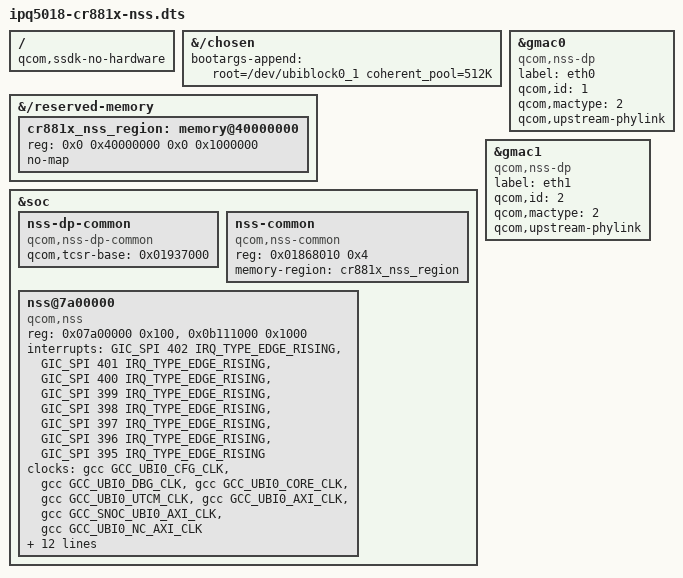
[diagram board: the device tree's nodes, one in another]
// SPDX-License-Identifier: (GPL-2.0+)
/* Native qosmio NSS variant. The ordinary CR881x DTS stays on stmmac. */
#include "ipq5018-cr881x.dts"

&{/chosen} {
	/* MPD temporary buffers use sleepable DMA allocations (patch 0828). */
	bootargs-append = " root=/dev/ubiblock0_1 coherent_pool=512K";
};

/ {
	/* SSDK provides link symbols only; YT921x and UNIPHY own the hardware. */
	qcom,ssdk-no-hardware;
};

&{/reserved-memory} {
	/* IPQ5018 MP firmware load region; opt-in for this 256 MiB profile. */
	cr881x_nss_region: memory@40000000 {
		reg = <0x0 0x40000000 0x0 0x1000000>;
		no-map;
	};
};

&soc {
	nss-dp-common {
		compatible = "qcom,nss-dp-common";
		qcom,tcsr-base = <0x01937000>;
	};

	nss-common {
		compatible = "qcom,nss-common";
		reg = <0x01868010 0x4>;
		reg-names = "nss-misc-reset";
		memory-region = <&cr881x_nss_region>;
	};

	nss@7a00000 {
		compatible = "qcom,nss";
		reg = <0x07a00000 0x100>, <0x0b111000 0x1000>;
		reg-names = "nphys", "qgic-phys";
		interrupts = <GIC_SPI 402 IRQ_TYPE_EDGE_RISING>,
			     <GIC_SPI 401 IRQ_TYPE_EDGE_RISING>,
			     <GIC_SPI 400 IRQ_TYPE_EDGE_RISING>,
			     <GIC_SPI 399 IRQ_TYPE_EDGE_RISING>,
			     <GIC_SPI 398 IRQ_TYPE_EDGE_RISING>,
			     <GIC_SPI 397 IRQ_TYPE_EDGE_RISING>,
			     <GIC_SPI 396 IRQ_TYPE_EDGE_RISING>,
			     <GIC_SPI 395 IRQ_TYPE_EDGE_RISING>;
		clocks = <&gcc GCC_UBI0_CFG_CLK>, <&gcc GCC_UBI0_DBG_CLK>,
			 <&gcc GCC_UBI0_CORE_CLK>, <&gcc GCC_UBI0_UTCM_CLK>,
			 <&gcc GCC_UBI0_AXI_CLK>, <&gcc GCC_SNOC_UBI0_AXI_CLK>,
			 <&gcc GCC_UBI0_NC_AXI_CLK>;
		clock-names = "nss-cfg-clk", "nss-dbg-clk", "nss-core-clk",
			      "nss-utcm-clk", "nss-axi-clk", "nss-snoc-axi-clk",
			      "nss-nc-axi-clk";
		qcom,id = <0>;
		qcom,num-queue = <4>;
		qcom,num-irq = <8>;
		qcom,num-pri = <4>;
		qcom,load-addr = <0x40000000>;
		qcom,low-frequency = <850000000>;
		qcom,mid-frequency = <1000000000>;
		qcom,max-frequency = <1000000000>;
		qcom,ipv4-enabled;
		qcom,ipv6-enabled;
		qcom,pppoe-enabled;
		/* Required to initialize the firmware VLAN message API. */
		qcom,vlan-enabled;
	};
};

/* Override the binding on the same MAC resources: one owner per MAC. */
&gmac0 {
	compatible = "qcom,nss-dp";
	label = "eth0";
	qcom,id = <1>;
	qcom,mactype = <2>;
	qcom,upstream-phylink;
};

&gmac1 {
	compatible = "qcom,nss-dp";
	label = "eth1";
	qcom,id = <2>;
	qcom,mactype = <2>;
	qcom,upstream-phylink;
};
